# PIC32CM3204PL10032 register map
Vendor: Microchip Technology; Series: PIC32CMPL10; File version: 0
CPU: CM0+ r0p0, little endian, no MPU, no FPU, VTOR, 2 interrupt priority bits, 15 interrupts
Registers are 32-bit, read-write, reset 0x0 unless marked. A register's access mark holds for its fields unless they carry their own. Offsets are from the block's base; [hi:lo] are bit positions; {n}, {i} and the like mark numbered series; 'fields as' and 'values as' point back to an identical list.

## OSC32KCTRL — 32.768 kHz Oscillators Controller
Base 0x40001400
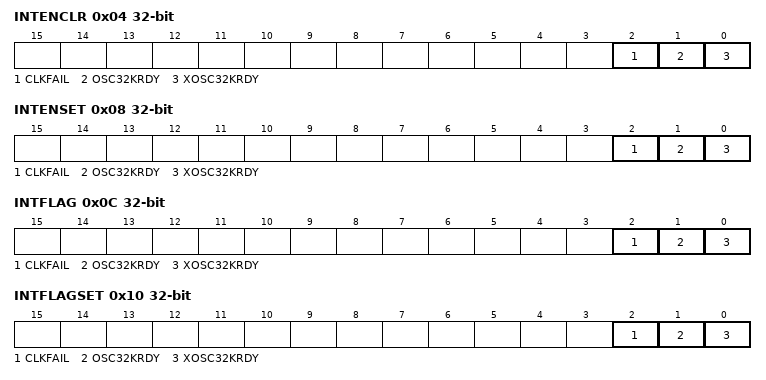
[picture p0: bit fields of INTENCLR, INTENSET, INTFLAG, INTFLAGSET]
0x04 INTENCLR write-1-clears — Interrupt Enable Clear
  [2] CLKFAIL — XOSC32K Clock Failure Detection Interrupt Enable
  [1] OSC32KRDY — OSC32K Ready Interrupt Enable
  [0] XOSC32KRDY — XOSC32K Ready Interrupt Enable
0x08 INTENSET write-1-sets — Interrupt Enable Set
  fields as INTENCLR
0x0C INTFLAG write-1-clears — Interrupt Flag Status and Clear
  [2] CLKFAIL — XOSC32K Clock Failure Detected
  [1] OSC32KRDY — OSC32K Ready
  [0] XOSC32KRDY — XOSC32K Ready
0x10 INTFLAGSET write-1-clears — Interrupt Flag Software Set
  fields as INTFLAG
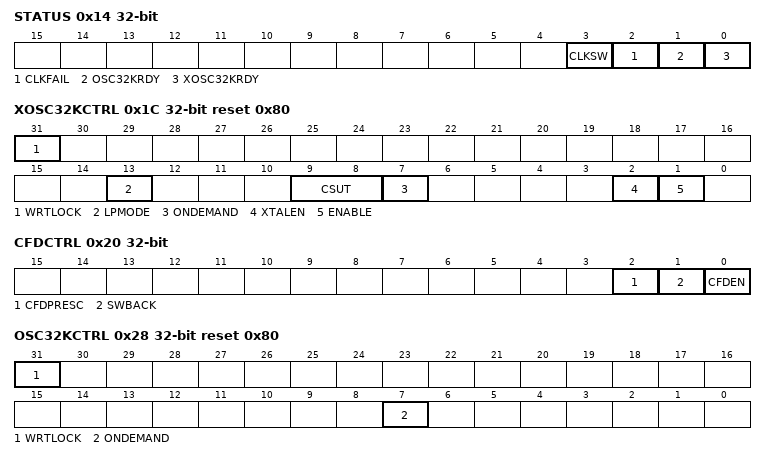
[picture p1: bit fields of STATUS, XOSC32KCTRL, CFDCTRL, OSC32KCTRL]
0x14 STATUS ro
  [3] CLKSW — XOSC32K Clock Switch
  [2] CLKFAIL — XOSC32K Clock Failure Detected
  [1] OSC32KRDY — OSC32K Ready
  [0] XOSC32KRDY — XOSC32K Ready
0x18 RTCCTRL — RTC Control
  [2:0] RTCSEL — RTC Clock Source Selection
    2=OSC1K (1.024 kHz from the internal 32.768 kHz oscillator); 3=OSC32K (32.768 kHz from the internal 32.768 kHz oscillator); 4=XOSC1K (1.024 kHz from the external 32.768 kHz crystal oscillator); 5=XOSC32K (32.768 kHz from the external 32.768 kHz crystal oscillator)
0x1C XOSC32KCTRL reset 0x80 — XOSC32K Control
  [31] WRTLOCK — Write Lock
  [13] LPMODE — Low Power Mode
  [9:8] CSUT — Crystal Oscillator Start-Up Time
    0=1K (1K XOSC32K cycles); 1=16K (16K XOSC32K cycles); 2=32K (32K XOSC32K cycles); 3=64K (64K XOSC32K cycles)
  [7] ONDEMAND — On-Demand Operation
  [2] XTALEN — External Source Select
    0=EXTCLK (External Clock on the XTAL32K1 pin. XTAL32K2 is available for other functions. The CSUT timer is disregarded, and no start-up time is used.); 1=XTAL (External Crystal connected to the XTAL32K1 and XTAL32K2 pins)
  [1] ENABLE — Oscillator Enable
0x20 CFDCTRL — Clock Failure Detector Control
  [2] CFDPRESC — Clock Failure Detector Prescaler
  [1] SWBACK — Clock Switch Back Enable
  [0] CFDEN — Clock Failure Detector Enable
0x24 EVCTRL — Event Control
  [0] CFDEO — Clock Failure Detector Event Output Enable
0x28 OSC32KCTRL reset 0x80 — 32.768 kHz Internal Oscillator (OSC32K) Control
  [31] WRTLOCK — Write Lock
  [7] ONDEMAND — On-Demand Operation
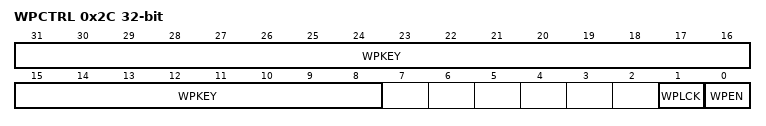
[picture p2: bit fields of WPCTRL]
0x2C WPCTRL — Write Protection Control
  [31:8] WPKEY — Write Protection Key
    0x4F5343=KEY (Allow writes to the WPCTRL register)
  [1] WPLCK — Write Protection Lock
  [0] WPEN — Write Protection Enable

## OSCCTRL — Oscillators Controller
Base 0x40001000
0x04 INTENCLR write-1-clears — Interrupt Enable Clear
  [4] OSCHFRDY — OSCHF Ready Interrupt Enable
0x08 INTENSET write-1-sets — Interrupt Enable Set
  [4] OSCHFRDY — OSCHF Ready Interrupt Enable
0x0C INTFLAG write-1-clears — Interrupt Flag Status and Clear
  [4] OSCHFRDY — OSCHF is Ready
0x10 INTFLAGSET write-1-clears — Interrupt Flag Software Set
  [4] OSCHFRDY — OSCHF is Ready
0x14 STATUS ro
  [4] OSCHFRDY — OSCHF is Ready
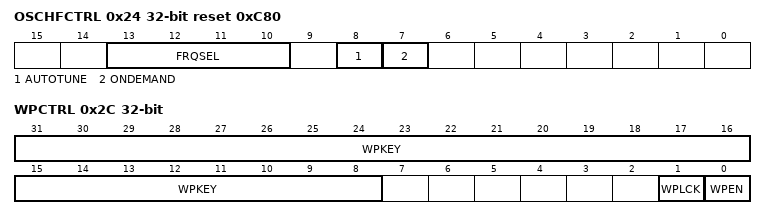
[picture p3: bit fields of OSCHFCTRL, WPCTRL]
0x24 OSCHFCTRL reset 0xC80 — OSCHF Control
  [13:10] FRQSEL — Frequency Select
    {v}={v+1}M ({v+1} MHz output clock) (v=0..3); 5=8M (8 MHz output clock); 6=12M (12 MHz output clock); 7=16M (16 MHz output clock); 8=20M (20 MHz output clock); 9=24M (24 MHz output clock)
  [8] AUTOTUNE — Automatic oscillator tune
    0=OFF (Automatic oscillator frequency tune disabled); 1=ON (Automatic oscillator frequency tune enabled)
  [7] ONDEMAND — On-Demand Operation
0x28 OSCHFTUNE — OSCHF Oscillator Frequency Tune
  [7:0] TUNE — Oscillator Tune
0x2C WPCTRL — Write Protection Control
  [31:8] WPKEY — Write Protection Key
    0x4F5343=KEY (Allow writes to the WPCTRL register)
  [1] WPLCK — Write Protection Lock
  [0] WPEN — Write Protection Enable

## Notices in the file
Copyright (c) 2026 Microchip Technology Inc.
SPDX-License-Identifier: Apache-2.0
Licensed under the Apache License, Version 2.0 (the "License");
you may not use this file except in compliance with the License.
You may obtain a copy of the License at
http://www.apache.org/licenses/LICENSE-2.0
Unless required by applicable law or agreed to in writing, software
distributed under the License is distributed on an "AS IS" BASIS,
WITHOUT WARRANTIES OR CONDITIONS OF ANY KIND, either express or implied.
See the License for the specific language governing permissions and
limitations under the License.
